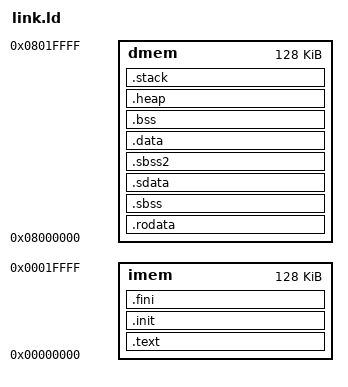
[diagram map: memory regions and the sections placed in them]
/*
    FreeRTOS V8.2.3 - Copyright (C) 2015 Real Time Engineers Ltd.
    All rights reserved

    VISIT http://www.FreeRTOS.org TO ENSURE YOU ARE USING THE LATEST VERSION.

    This file is part of the FreeRTOS distribution and was contributed
    to the project by Technolution B.V. (www.technolution.nl,
    freertos-riscv@technolution.eu) under the terms of the FreeRTOS
    contributors license.

    FreeRTOS is free software; you can redistribute it and/or modify it under
    the terms of the GNU General Public License (version 2) as published by the
    Free Software Foundation >>>> AND MODIFIED BY <<<< the FreeRTOS exception.

    ***************************************************************************
    >>!   NOTE: The modification to the GPL is included to allow you to     !<<
    >>!   distribute a combined work that includes FreeRTOS without being   !<<
    >>!   obliged to provide the source code for proprietary components     !<<
    >>!   outside of the FreeRTOS kernel.                                   !<<
    ***************************************************************************

    FreeRTOS is distributed in the hope that it will be useful, but WITHOUT ANY
    WARRANTY; without even the implied warranty of MERCHANTABILITY or FITNESS
    FOR A PARTICULAR PURPOSE.  Full license text is available on the following
    link: http://www.freertos.org/a00114.html

    ***************************************************************************
     *                                                                       *
     *    FreeRTOS provides completely free yet professionally developed,    *
     *    robust, strictly quality controlled, supported, and cross          *
     *    platform software that is more than just the market leader, it     *
     *    is the industry's de facto standard.                               *
     *                                                                       *
     *    Help yourself get started quickly while simultaneously helping     *
     *    to support the FreeRTOS project by purchasing a FreeRTOS           *
     *    tutorial book, reference manual, or both:                          *
     *    http://www.FreeRTOS.org/Documentation                              *
     *                                                                       *
    ***************************************************************************

    http://www.FreeRTOS.org/FAQHelp.html - Having a problem?  Start by reading
    the FAQ page "My application does not run, what could be wrong?".  Have you
    defined configASSERT()?

    http://www.FreeRTOS.org/support - In return for receiving this top quality
    embedded software for free we request you assist our global community by
    participating in the support forum.

    http://www.FreeRTOS.org/training - Investing in training allows your team to
    be as productive as possible as early as possible.  Now you can receive
    FreeRTOS training directly from Richard Barry, CEO of Real Time Engineers
    Ltd, and the world's leading authority on the world's leading RTOS.

    http://www.FreeRTOS.org/plus - A selection of FreeRTOS ecosystem products,
    including FreeRTOS+Trace - an indispensable productivity tool, a DOS
    compatible FAT file system, and our tiny thread aware UDP/IP stack.

    http://www.FreeRTOS.org/labs - Where new FreeRTOS products go to incubate.
    Come and try FreeRTOS+TCP, our new open source TCP/IP stack for FreeRTOS.

    http://www.OpenRTOS.com - Real Time Engineers ltd. license FreeRTOS to High
    Integrity Systems ltd. to sell under the OpenRTOS brand.  Low cost OpenRTOS
    licenses offer ticketed support, indemnification and commercial middleware.

    http://www.SafeRTOS.com - High Integrity Systems also provide a safety
    engineered and independently SIL3 certified version for use in safety and
    mission critical applications that require provable dependability.

    1 tab == 4 spaces!
*/

/*设置输出文件的machine architecture*/
OUTPUT_ARCH( "riscv" )


_STACK_SIZE = DEFINED(_STACK_SIZE) ? _STACK_SIZE : 0x1000;
_HEAP_SIZE = DEFINED(_HEAP_SIZE) ? _HEAP_SIZE : 0x1000;

/*****************************************************************************
 * Define memory layout
 ****************************************************************************/
/*在默认情形下，连接器可以为section分配任意位置的存储区域。也可以用MEMORY命令定义存储区域，并通过输出section描述的> REGION属性显示地将该输出section限定于某块存储区域，当存储区域大小不能满足要求时，连接器会报告该错误。*/
MEMORY {
	imem : ORIGIN = 0x00000000, LENGTH = 0x00020000
	dmem : ORIGIN = 0x08000000, LENGTH = 0x00020000
}

/* Specify the default entry point to the program */
/*定义入口*/
ENTRY(_mstart)

/*****************************************************************************
 * Define the sections, and where they are mapped in memory 
 ****************************************************************************/
SECTIONS {
	.text : {
        /* "." 是定位符号*/
		. = 0x100;
	    *bootasm.o(.text);/*boot.o文件的.text section*/
		*(.text);/*表示所有输入文件的.text section*/
		*(.text.*);
	} > imem

	.init : {
/*在连接命令行内使用了选项–gc-sections后，连接器可能将某些它认为没用的section过滤掉，此时就有必要强制连接器保留一些特定的 section，可用KEEP()关键字达此目的*/
	   KEEP (*(.init))
	} > imem

    .fini : {
       KEEP (*(.fini))
    } > imem
/*?*/

    PROVIDE(etext = .);	/* Define the 'etext' symbol to this value */

   /*在ELF格式的可执行文件中，全局内存包括三种：bss、data和rodata ro是readonly的意思*/
      .rodata : {
       __rodata_start = .;
       *(.rodata)
       *(.rodata.*)
       *(.gnu.linkonce.r.*)
       __rodata_end = .;
	} > dmem

   /* Include debugging information in kernel memory */
	.stab : {
		PROVIDE(__STAB_BEGIN__ = .);
		*(.stab);
		PROVIDE(__STAB_END__ = .);
		BYTE(0)		/* Force the linker to allocate space
				   for this section */
	}

	.stabstr : {
		PROVIDE(__STABSTR_BEGIN__ = .);
		*(.stabstr);
		PROVIDE(__STABSTR_END__ = .);
		BYTE(0)		/* Force the linker to allocate space
				   for this section */
	}


	.sbss : {
	   __sbss_start = .;
	   *(.sbss)
	   *(.sbss.*)
	   *(.gnu.linkonce.sb.*)
	   __sbss_end = .;
	} > dmem
	
      .sdata : {
        _gp = . + 0x800;
        *(.srodata.cst16) *(.srodata.cst8) *(.srodata.cst4) *(.srodata.cst2) *(.srodata*)
        *(.sdata .sdata.* .gnu.linkonce.s.*)
     }	> dmem

	.sbss2 : {
	   __sbss2_start = .;
	   *(.sbss2)
	   *(.sbss2.*)
	   *(.gnu.linkonce.sb2.*)
	   __sbss2_end = .;
	} > dmem



	.data : {
	   . = ALIGN(4);
	   __data_start = .;
	   *(.data)
	   *(.data.*)
	   *(.gnu.linkonce.d.*)
	   __data_end = .;
	} > dmem

    .bss : {
       . = ALIGN(4);
       __bss_start = .;
       *(.bss)
       *(.bss.*)
       *(.gnu.linkonce.b.*)
       *(COMMON)
       . = ALIGN(4);
       __bss_end = .;
    } > dmem

    /* Generate Stack and Heap definitions */

    .heap : {
       . = ALIGN(4);
       _heap = .;
       _heap_start = .;
       . += _HEAP_SIZE;
       _heap_end = .;
    } > dmem

    .stack : {
       _stack_end = .;
       . += _STACK_SIZE;
       . = ALIGN(4);
       _stack = .;
       __stack = _stack;
    } > dmem
    
    _end = .;
}
